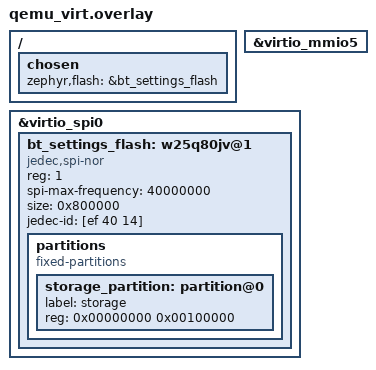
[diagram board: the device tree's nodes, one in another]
/*
 * Dedicated W25Q80 for Bluetooth settings on virtio-spi CS1.
 *
 * The general virtio-spi snippet uses a persistent NOR on CS0 for SPI-flash
 * and LittleFS samples. Bluetooth gets a separate simulated chip so NVS and
 * LittleFS never interpret or overwrite each other's on-flash formats.
 */

&virtio_mmio5 {
	status = "okay";
};

&virtio_spi0 {
	status = "okay";

	bt_settings_flash: w25q80jv@1 {
		compatible = "jedec,spi-nor";
		reg = <1>;
		spi-max-frequency = <40000000>;
		size = <0x800000>; /* 1 MiB */
		jedec-id = [ef 40 14];
		status = "okay";

		partitions {
			compatible = "fixed-partitions";
			#address-cells = <1>;
			#size-cells = <1>;

			storage_partition: partition@0 {
				label = "storage";
				reg = <0x00000000 0x00100000>;
			};
		};
	};
};

/ {
	chosen {
		zephyr,flash = &bt_settings_flash;
	};
};
